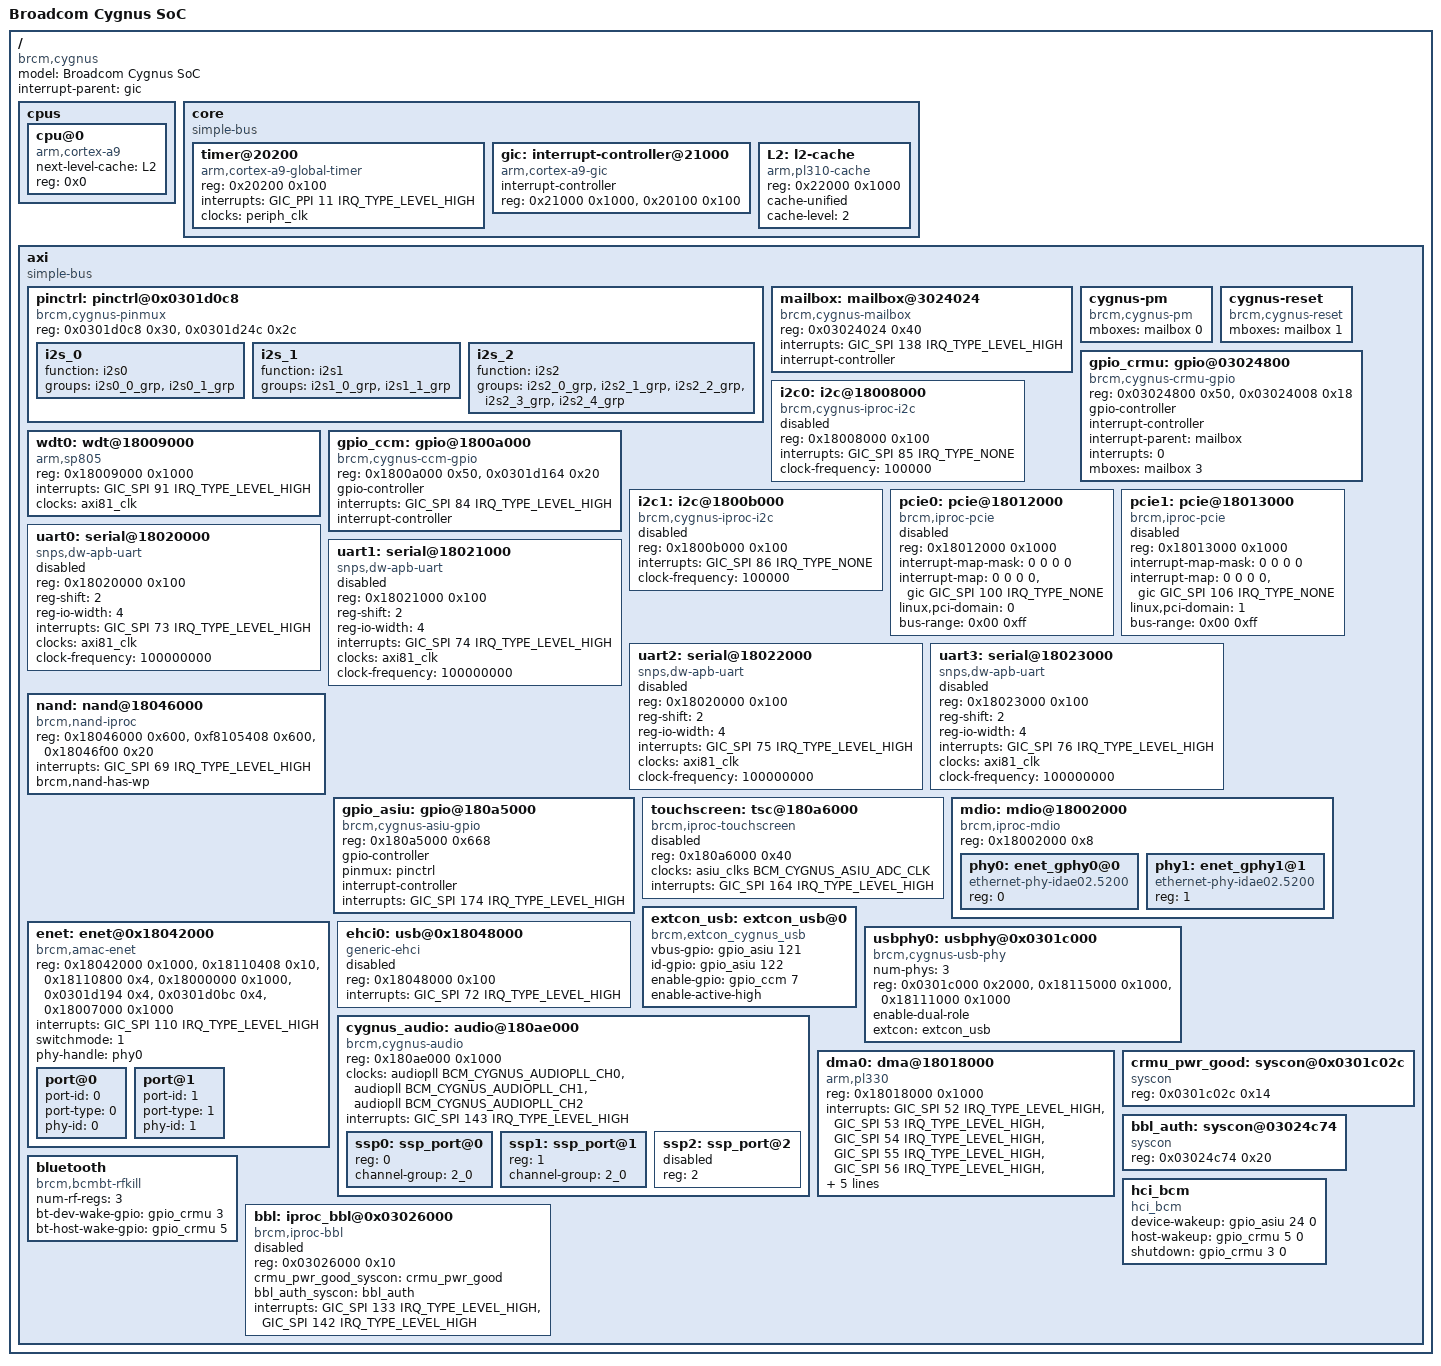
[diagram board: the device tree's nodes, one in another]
/*
 *  BSD LICENSE
 *
 *  Copyright(c) 2014 Broadcom Corporation.  All rights reserved.
 *
 *  Redistribution and use in source and binary forms, with or without
 *  modification, are permitted provided that the following conditions
 *  are met:
 *
 *    * Redistributions of source code must retain the above copyright
 *      notice, this list of conditions and the following disclaimer.
 *    * Redistributions in binary form must reproduce the above copyright
 *      notice, this list of conditions and the following disclaimer in
 *      the documentation and/or other materials provided with the
 *      distribution.
 *    * Neither the name of Broadcom Corporation nor the names of its
 *      contributors may be used to endorse or promote products derived
 *      from this software without specific prior written permission.
 *
 *  THIS SOFTWARE IS PROVIDED BY THE COPYRIGHT HOLDERS AND CONTRIBUTORS
 *  "AS IS" AND ANY EXPRESS OR IMPLIED WARRANTIES, INCLUDING, BUT NOT
 *  LIMITED TO, THE IMPLIED WARRANTIES OF MERCHANTABILITY AND FITNESS FOR
 *  A PARTICULAR PURPOSE ARE DISCLAIMED. IN NO EVENT SHALL THE COPYRIGHT
 *  OWNER OR CONTRIBUTORS BE LIABLE FOR ANY DIRECT, INDIRECT, INCIDENTAL,
 *  SPECIAL, EXEMPLARY, OR CONSEQUENTIAL DAMAGES (INCLUDING, BUT NOT
 *  LIMITED TO, PROCUREMENT OF SUBSTITUTE GOODS OR SERVICES; LOSS OF USE,
 *  DATA, OR PROFITS; OR BUSINESS INTERRUPTION) HOWEVER CAUSED AND ON ANY
 *  THEORY OF LIABILITY, WHETHER IN CONTRACT, STRICT LIABILITY, OR TORT
 *  (INCLUDING NEGLIGENCE OR OTHERWISE) ARISING IN ANY WAY OUT OF THE USE
 * OF THIS SOFTWARE, EVEN IF ADVISED OF THE POSSIBILITY OF SUCH DAMAGE.
 */

#include <dt-bindings/interrupt-controller/arm-gic.h>
#include <dt-bindings/interrupt-controller/irq.h>
#include <dt-bindings/clock/bcm-cygnus.h>

#include "skeleton.dtsi"

/ {
	compatible = "brcm,cygnus";
	model = "Broadcom Cygnus SoC";
	interrupt-parent = <&gic>;

	cpus {
		#address-cells = <1>;
		#size-cells = <0>;

		cpu@0 {
			device_type = "cpu";
			compatible = "arm,cortex-a9";
			next-level-cache = <&L2>;
			reg = <0x0>;
		};
	};

	/include/ "bcm-cygnus-clock.dtsi"

	core {
		compatible = "simple-bus";
		ranges = <0x00000000 0x19000000 0x1000000>;
		#address-cells = <1>;
		#size-cells = <1>;

		timer@20200 {
			compatible = "arm,cortex-a9-global-timer";
			reg = <0x20200 0x100>;
			interrupts = <GIC_PPI 11 IRQ_TYPE_LEVEL_HIGH>;
			clocks = <&periph_clk>;
		};

		gic: interrupt-controller@21000 {
			compatible = "arm,cortex-a9-gic";
			#interrupt-cells = <3>;
			#address-cells = <0>;
			interrupt-controller;
			reg = <0x21000 0x1000>,
			      <0x20100 0x100>;
		};

		L2: l2-cache {
			compatible = "arm,pl310-cache";
			reg = <0x22000 0x1000>;
			cache-unified;
			cache-level = <2>;
		};
	};

	axi {
		compatible = "simple-bus";
		ranges;
		#address-cells = <1>;
		#size-cells = <1>;

		pinctrl: pinctrl@0x0301d0c8 {
			compatible = "brcm,cygnus-pinmux";
			reg = <0x0301d0c8 0x30>,
			      <0x0301d24c 0x2c>;
			i2s_0: i2s_0 {
				function = "i2s0";
				groups = "i2s0_0_grp", "i2s0_1_grp";
			};

			i2s_1: i2s_1 {
				function = "i2s1";
				groups = "i2s1_0_grp", "i2s1_1_grp";
			};

			i2s_2: i2s_2 {
				function = "i2s2";
				groups = "i2s2_0_grp", "i2s2_1_grp", "i2s2_2_grp",
				 	"i2s2_3_grp", "i2s2_4_grp";
			};
		};

		mailbox: mailbox@3024024 {
			compatible = "brcm,cygnus-mailbox";
			reg = <0x03024024 0x40>;
			interrupts = <GIC_SPI 138 IRQ_TYPE_LEVEL_HIGH>;
			#interrupt-cells = <1>;
			interrupt-controller;
			#mbox-cells = <1>;
		};

		cygnus-pm {
			compatible = "brcm,cygnus-pm";
			mboxes = <&mailbox 0>;
		};

		cygnus-reset {
			compatible = "brcm,cygnus-reset";
			mboxes = <&mailbox 1>;
		};

		gpio_crmu: gpio@03024800 {
			compatible = "brcm,cygnus-crmu-gpio";
			reg = <0x03024800 0x50>,
			      <0x03024008 0x18>;
			#gpio-cells = <2>;
			gpio-controller;
			interrupt-controller;
			interrupt-parent = <&mailbox>;
			interrupts = <0>;
			mboxes = <&mailbox 3>;

		};

/* -------------------------
		gpio_asiu: gpio@180a5000 {
			compatible = "brcm,cygnus-gpio";
			reg = <0x180a5000 0x668>;
			ngpios = <146>;
			linux,gpio-base = <24>;
			#gpio-cells = <2>;
			gpio-controller;

			pinmux = <&pinctrl>;	

			interrupt-controller;
			interrupts = <GIC_SPI 174 IRQ_TYPE_LEVEL_HIGH>;
		};
------------------- */
		i2c0: i2c@18008000 {
			compatible = "brcm,cygnus-iproc-i2c", "brcm,iproc-i2c";
			reg = <0x18008000 0x100>;
			#address-cells = <1>;
			#size-cells = <0>;
			interrupts = <GIC_SPI 85 IRQ_TYPE_NONE>;
			clock-frequency = <100000>;
			status = "disabled";
		};

		wdt0: wdt@18009000 {
			compatible = "arm,sp805" , "arm,primecell";
			reg = <0x18009000 0x1000>;
			interrupts = <GIC_SPI 91 IRQ_TYPE_LEVEL_HIGH>;
			clocks = <&axi81_clk>;
			clock-names = "apb_pclk";
		};

		gpio_ccm: gpio@1800a000 {
			compatible = "brcm,cygnus-ccm-gpio";
			reg = <0x1800a000 0x50>,
			      <0x0301d164 0x20>;
			#gpio-cells = <2>;
			gpio-controller;
			interrupts = <GIC_SPI 84 IRQ_TYPE_LEVEL_HIGH>;
			interrupt-controller;
		};

		i2c1: i2c@1800b000 {
			compatible = "brcm,cygnus-iproc-i2c", "brcm,iproc-i2c";
			reg = <0x1800b000 0x100>;
			#address-cells = <1>;
			#size-cells = <0>;
			interrupts = <GIC_SPI 86 IRQ_TYPE_NONE>;
			clock-frequency = <100000>;
			status = "disabled";
		};

		pcie0: pcie@18012000 {
			compatible = "brcm,iproc-pcie";
			reg = <0x18012000 0x1000>;

			#interrupt-cells = <1>;
			interrupt-map-mask = <0 0 0 0>;
			interrupt-map = <0 0 0 0 &gic GIC_SPI 100 IRQ_TYPE_NONE>;

			linux,pci-domain = <0>;

			bus-range = <0x00 0xff>;

			#address-cells = <3>;
			#size-cells = <2>;
			device_type = "pci";
			ranges = <0x81000000 0 0	  0x28000000 0 0x00010000
				  0x82000000 0 0x20000000 0x20000000 0 0x04000000>;

			status = "disabled";
		};

		pcie1: pcie@18013000 {
			compatible = "brcm,iproc-pcie";
			reg = <0x18013000 0x1000>;

			#interrupt-cells = <1>;
			interrupt-map-mask = <0 0 0 0>;
			interrupt-map = <0 0 0 0 &gic GIC_SPI 106 IRQ_TYPE_NONE>;

			linux,pci-domain = <1>;

			bus-range = <0x00 0xff>;

			#address-cells = <3>;
			#size-cells = <2>;
			device_type = "pci";
			ranges = <0x81000000 0 0	  0x48000000 0 0x00010000
				  0x82000000 0 0x40000000 0x40000000 0 0x04000000>;

			status = "disabled";
		};

		uart0: serial@18020000 {
			compatible = "snps,dw-apb-uart";
			reg = <0x18020000 0x100>;
			reg-shift = <2>;
			reg-io-width = <4>;
			interrupts = <GIC_SPI 73 IRQ_TYPE_LEVEL_HIGH>;
			clocks = <&axi81_clk>;
			clock-frequency = <100000000>;
			status = "disabled";
		};

		uart1: serial@18021000 {
			compatible = "snps,dw-apb-uart";
			reg = <0x18021000 0x100>;
			reg-shift = <2>;
			reg-io-width = <4>;
			interrupts = <GIC_SPI 74 IRQ_TYPE_LEVEL_HIGH>;
			clocks = <&axi81_clk>;
			clock-frequency = <100000000>;
			status = "disabled";
		};

		uart2: serial@18022000 {
			compatible = "snps,dw-apb-uart";
			reg = <0x18020000 0x100>;
			reg-shift = <2>;
			reg-io-width = <4>;
			interrupts = <GIC_SPI 75 IRQ_TYPE_LEVEL_HIGH>;
			clocks = <&axi81_clk>;
			clock-frequency = <100000000>;
			status = "disabled";
		};

		uart3: serial@18023000 {
			compatible = "snps,dw-apb-uart";
			reg = <0x18023000 0x100>;
			reg-shift = <2>;
			reg-io-width = <4>;
			interrupts = <GIC_SPI 76 IRQ_TYPE_LEVEL_HIGH>;
			clocks = <&axi81_clk>;
			clock-frequency = <100000000>;
			status = "disabled";
		};

		nand: nand@18046000 {
			compatible = "brcm,nand-iproc", "brcm,brcmnand-v6.1";
			reg = <0x18046000 0x600>, <0xf8105408 0x600>,
			      <0x18046f00 0x20>;
			reg-names = "nand", "iproc-idm", "iproc-ext";
			interrupts = <GIC_SPI 69 IRQ_TYPE_LEVEL_HIGH>;

			#address-cells = <1>;
			#size-cells = <0>;

			brcm,nand-has-wp;
		};

		gpio_asiu: gpio@180a5000 {
			compatible = "brcm,cygnus-asiu-gpio";
			reg = <0x180a5000 0x668>;
			#gpio-cells = <2>;
			gpio-controller;

			pinmux = <&pinctrl>;

			interrupt-controller;
			interrupts = <GIC_SPI 174 IRQ_TYPE_LEVEL_HIGH>;
		};

		touchscreen: tsc@180a6000 {
			compatible = "brcm,iproc-touchscreen";
			reg = <0x180a6000 0x40>;
			clocks = <&asiu_clks BCM_CYGNUS_ASIU_ADC_CLK>;
			clock-names = "tsc_clk";
			interrupts = <GIC_SPI 164 IRQ_TYPE_LEVEL_HIGH>;
			status = "disabled";
		};
/* ------------- [ADK] --------------------*/
		mdio: mdio@18002000 {
			compatible = "brcm,iproc-mdio";
			reg = <0x18002000 0x8>;
			#size-cells = <1>;
			#address-cells = <0>;

				phy0: enet_gphy0@0 {
					compatible = "ethernet-phy-idae02.5200";
					reg = <0>;
			};
				phy1: enet_gphy1@1 {
					compatible = "ethernet-phy-idae02.5200";
					reg = <1>;
			};
		};

		enet: enet@0x18042000 {
			compatible = "brcm,amac-enet";
			reg = <0x18042000 0x1000>,
		      		<0x18110408 0x10>,
		      		<0x18110800 0x4>,
		      		<0x18000000 0x1000>,
		      		<0x0301d194 0x4>,
		      		<0x0301d0bc 0x4>,
		      		<0x18007000 0x1000>;
			reg-names = "core_base",
				"amac_io_ctrl",
				"amac_idm_reset",
				"icfg",
				"switch_global_base",
				"crmu_io_pad_ctrl",
				"srab_base";
			interrupts = <GIC_SPI 110 IRQ_TYPE_LEVEL_HIGH>;
			switchmode = <1>;
			status="okay";
			phy-handle = <&phy0>;

			port@0 {
				port-id = <0>;
				port-type = <0>;
				phy-id = <0>;
			};

			port@1 {
				port-id = <1>;
				port-type = <1>;
				phy-id = <1>;
			};
		};

		extcon_usb: extcon_usb@0 {
			compatible = "brcm,extcon_cygnus_usb";
			vbus-gpio = <&gpio_asiu 121 0>;
			id-gpio = <&gpio_asiu 122 0>;
			enable-gpio = <&gpio_ccm 7 0>;   
			enable-active-high;
			status = "okay";
		};

		usbphy0: usbphy@0x0301c000 {
			#phy-cells = <2>;
			num-phys = <3>;
			compatible = "brcm,cygnus-usb-phy";
			reg = <0x0301c000 0x2000>,
		      		<0x18115000 0x1000>,
		      		<0x18111000 0x1000>;
			enable-dual-role;
			extcon = <&extcon_usb>;
			status = "okay";
		};

		ehci0: usb@0x18048000 {
			compatible = "generic-ehci";
			reg = <0x18048000 0x100>;
			interrupts = <GIC_SPI 72 IRQ_TYPE_LEVEL_HIGH>;
			status = "disabled";
		};

		cygnus_audio: audio@180ae000 {
			compatible = "brcm,cygnus-audio";
			#address-cells = <1>;
			#size-cells = <0>;

			reg = <0x180ae000 0x1000>;
/* --------------------------------------
			reg = <0x180ae000 0xafd>, <0x180aec00 0x1f8>;
			reg-names = "aud", "i2s_in";
----------- */	
			clocks = <&audiopll BCM_CYGNUS_AUDIOPLL_CH0>,
					<&audiopll BCM_CYGNUS_AUDIOPLL_CH1>,
					<&audiopll BCM_CYGNUS_AUDIOPLL_CH2>;

			clock-names = "ch0_audio", "ch1_audio", "ch2_audio";

			interrupts = <GIC_SPI 143 IRQ_TYPE_LEVEL_HIGH>;
			status = "okay";

			ssp0: ssp_port@0 {
				reg = <0>;
				channel-group = "2_0"; /* Use 2_0, 3_1, 5_1 */
				status = "okay";
			};

			ssp1: ssp_port@1 {
				reg = <1>;
				channel-group = "2_0"; /* Use 2_0, 3_1, 5_1 */
				status = "okay";
			};

			ssp2: ssp_port@2 {
				reg = <2>;
				status = "disabled";
			};
		};

		dma0: dma@18018000 {
			compatible = "arm,pl330", "arm,primecell";
			reg = <0x18018000 0x1000>;
			interrupts = <GIC_SPI 52 IRQ_TYPE_LEVEL_HIGH>,
				     <GIC_SPI 53 IRQ_TYPE_LEVEL_HIGH>,
				     <GIC_SPI 54 IRQ_TYPE_LEVEL_HIGH>,
				     <GIC_SPI 55 IRQ_TYPE_LEVEL_HIGH>,
				     <GIC_SPI 56 IRQ_TYPE_LEVEL_HIGH>,
				     <GIC_SPI 57 IRQ_TYPE_LEVEL_HIGH>,
				     <GIC_SPI 58 IRQ_TYPE_LEVEL_HIGH>,
				     <GIC_SPI 59 IRQ_TYPE_LEVEL_HIGH>,
				     <GIC_SPI 67 IRQ_TYPE_LEVEL_HIGH>;
			clocks = <&apb_clk>;
			clock-names = "apb_pclk";
			#dma-cells = <1>;
		};

		crmu_pwr_good: syscon@0x0301c02c {
			compatible = "syscon";
			reg = < 0x0301c02c 0x14>;
		};

		bbl_auth: syscon@03024c74 {
			compatible = "syscon";
			reg = <0x03024c74 0x20>;
		};

		bluetooth {
			compatible = "brcm,bcmbt-rfkill";
			num-rf-regs = <3>;
			bt-dev-wake-gpio = <&gpio_crmu 3 0>;
			bt-host-wake-gpio = <&gpio_crmu 5 0>;
		};

		hci_bcm {
			compatible = "hci_bcm";
			device-wakeup = <&gpio_asiu 24 0>;
			host-wakeup = <&gpio_crmu 5 0>;
			shutdown = <&gpio_crmu 3 0>;
		};

		bbl: iproc_bbl@0x03026000 {
			compatible = "brcm,iproc-bbl";
			reg = <0x03026000 0x10>;
			crmu_pwr_good_syscon = <&crmu_pwr_good>;
			bbl_auth_syscon = <&bbl_auth>;
			interrupts = <GIC_SPI 133 IRQ_TYPE_LEVEL_HIGH>,
			<GIC_SPI 142 IRQ_TYPE_LEVEL_HIGH>;
			status = "disabled";
		};
/*----------------------------------------*/
	};
};
